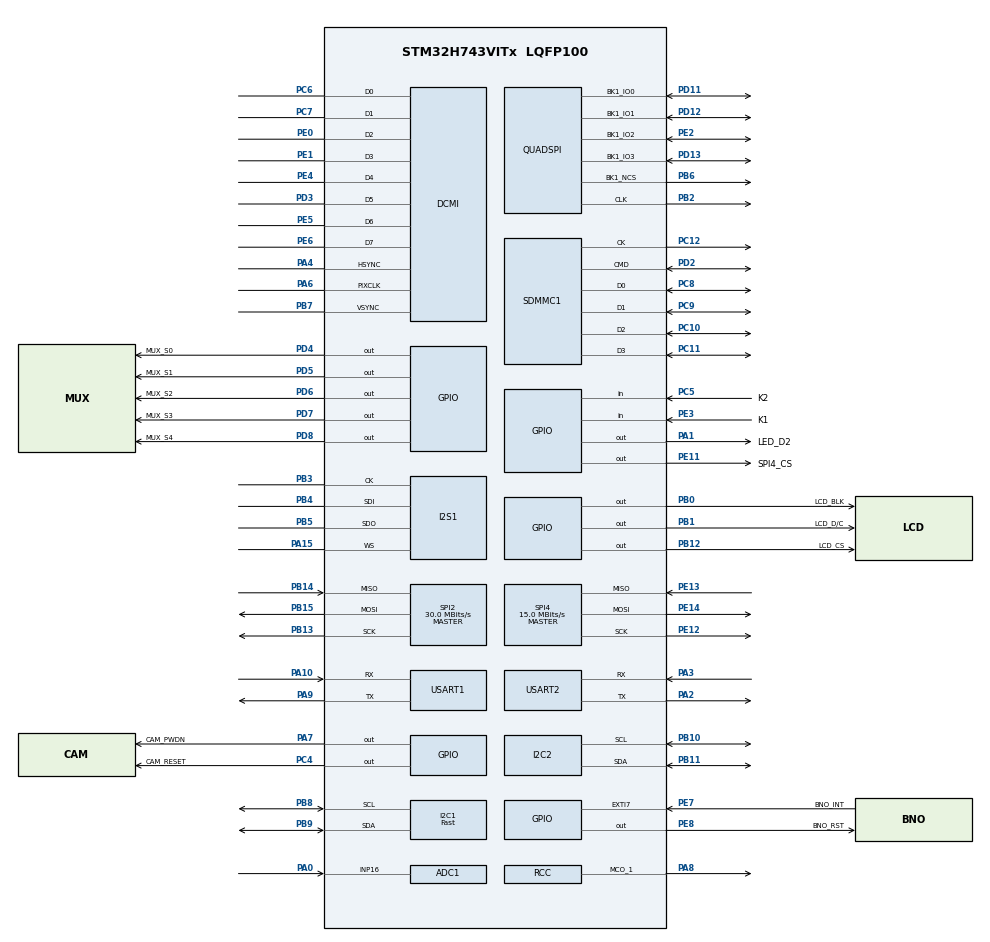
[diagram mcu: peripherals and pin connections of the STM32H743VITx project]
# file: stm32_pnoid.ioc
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ADC1.Channel-0\#ChannelRegularConversion=ADC_CHANNEL_16
ADC1.ClockPrescaler=ADC_CLOCK_ASYNC_DIV4
ADC1.NbrOfConversionFlag=1
ADC1.OffsetNumber-0\#ChannelRegularConversion=ADC_OFFSET_NONE
ADC1.OffsetSignedSaturation-0\#ChannelRegularConversion=DISABLE
ADC1.Rank-0\#ChannelRegularConversion=1
ADC1.Resolution=ADC_RESOLUTION_12B
ADC1.SamplingTime-0\#ChannelRegularConversion=ADC_SAMPLETIME_64CYCLES_5
ADC1.master=1
CORTEX_M7.CPU_ICache=Enabled
CORTEX_M7.default_mode_Activation=1
Dma.DCMI.0.Direction=DMA_PERIPH_TO_MEMORY
Dma.DCMI.0.EventEnable=DISABLE
Dma.DCMI.0.FIFOMode=DMA_FIFOMODE_DISABLE
Dma.DCMI.0.Instance=DMA1_Stream0
Dma.DCMI.0.MemDataAlignment=DMA_MDATAALIGN_WORD
Dma.DCMI.0.MemInc=DMA_MINC_ENABLE
Dma.DCMI.0.Mode=DMA_CIRCULAR
Dma.DCMI.0.PeriphDataAlignment=DMA_PDATAALIGN_WORD
Dma.DCMI.0.PeriphInc=DMA_PINC_DISABLE
Dma.DCMI.0.Polarity=HAL_DMAMUX_REQ_GEN_RISING
Dma.DCMI.0.Priority=DMA_PRIORITY_HIGH
Dma.DCMI.0.RequestNumber=1
Dma.DCMI.0.SignalID=NONE
Dma.DCMI.0.SyncEnable=DISABLE
Dma.DCMI.0.SyncPolarity=HAL_DMAMUX_SYNC_NO_EVENT
Dma.DCMI.0.SyncRequestNumber=1
Dma.DCMI.0.SyncSignalID=NONE
Dma.Request0=DCMI
Dma.Request1=SPI1_TX
Dma.Request2=SPI2_TX
Dma.Request3=SPI4_RX
Dma.Request4=SPI4_TX
Dma.SPI1_TX.1.Direction=DMA_MEMORY_TO_PERIPH
Dma.SPI1_TX.1.EventEnable=DISABLE
Dma.SPI1_TX.1.FIFOMode=DMA_FIFOMODE_DISABLE
Dma.SPI1_TX.1.Instance=DMA1_Stream1
Dma.SPI1_TX.1.MemDataAlignment=DMA_MDATAALIGN_HALFWORD
Dma.SPI1_TX.1.MemInc=DMA_MINC_ENABLE
Dma.SPI1_TX.1.Mode=DMA_CIRCULAR
Dma.SPI1_TX.1.PeriphDataAlignment=DMA_PDATAALIGN_HALFWORD
Dma.SPI1_TX.1.PeriphInc=DMA_PINC_DISABLE
Dma.SPI1_TX.1.Polarity=HAL_DMAMUX_REQ_GEN_RISING
Dma.SPI1_TX.1.Priority=DMA_PRIORITY_HIGH
Dma.SPI1_TX.1.RequestNumber=1
Dma.SPI1_TX.1.SignalID=NONE
Dma.SPI1_TX.1.SyncEnable=DISABLE
Dma.SPI1_TX.1.SyncPolarity=HAL_DMAMUX_SYNC_NO_EVENT
Dma.SPI1_TX.1.SyncRequestNumber=1
Dma.SPI1_TX.1.SyncSignalID=NONE
Dma.SPI2_TX.2.Direction=DMA_MEMORY_TO_PERIPH
Dma.SPI2_TX.2.EventEnable=DISABLE
Dma.SPI2_TX.2.FIFOMode=DMA_FIFOMODE_DISABLE
Dma.SPI2_TX.2.Instance=DMA1_Stream2
Dma.SPI2_TX.2.MemDataAlignment=DMA_MDATAALIGN_BYTE
Dma.SPI2_TX.2.MemInc=DMA_MINC_ENABLE
Dma.SPI2_TX.2.Mode=DMA_NORMAL
Dma.SPI2_TX.2.PeriphDataAlignment=DMA_PDATAALIGN_BYTE
Dma.SPI2_TX.2.PeriphInc=DMA_PINC_DISABLE
Dma.SPI2_TX.2.Polarity=HAL_DMAMUX_REQ_GEN_RISING
Dma.SPI2_TX.2.Priority=DMA_PRIORITY_MEDIUM
Dma.SPI2_TX.2.RequestNumber=1
Dma.SPI2_TX.2.SignalID=NONE
Dma.SPI2_TX.2.SyncEnable=DISABLE
Dma.SPI2_TX.2.SyncPolarity=HAL_DMAMUX_SYNC_NO_EVENT
Dma.SPI2_TX.2.SyncRequestNumber=1
Dma.SPI2_TX.2.SyncSignalID=NONE
Dma.SPI4_RX.3.Direction=DMA_PERIPH_TO_MEMORY
Dma.SPI4_RX.3.EventEnable=DISABLE
Dma.SPI4_RX.3.FIFOMode=DMA_FIFOMODE_DISABLE
Dma.SPI4_RX.3.Instance=DMA1_Stream3
Dma.SPI4_RX.3.MemDataAlignment=DMA_MDATAALIGN_BYTE
Dma.SPI4_RX.3.MemInc=DMA_MINC_ENABLE
Dma.SPI4_RX.3.Mode=DMA_NORMAL
Dma.SPI4_RX.3.PeriphDataAlignment=DMA_PDATAALIGN_BYTE
Dma.SPI4_RX.3.PeriphInc=DMA_PINC_DISABLE
Dma.SPI4_RX.3.Polarity=HAL_DMAMUX_REQ_GEN_RISING
Dma.SPI4_RX.3.Priority=DMA_PRIORITY_MEDIUM
Dma.SPI4_RX.3.RequestNumber=1
Dma.SPI4_RX.3.SignalID=NONE
Dma.SPI4_RX.3.SyncEnable=DISABLE
Dma.SPI4_RX.3.SyncPolarity=HAL_DMAMUX_SYNC_NO_EVENT
Dma.SPI4_RX.3.SyncRequestNumber=1
Dma.SPI4_RX.3.SyncSignalID=NONE
Dma.SPI4_TX.4.Direction=DMA_MEMORY_TO_PERIPH
Dma.SPI4_TX.4.EventEnable=DISABLE
Dma.SPI4_TX.4.FIFOMode=DMA_FIFOMODE_DISABLE
Dma.SPI4_TX.4.Instance=DMA1_Stream4
Dma.SPI4_TX.4.MemDataAlignment=DMA_MDATAALIGN_BYTE
Dma.SPI4_TX.4.MemInc=DMA_MINC_ENABLE
Dma.SPI4_TX.4.Mode=DMA_NORMAL
Dma.SPI4_TX.4.PeriphDataAlignment=DMA_PDATAALIGN_BYTE
Dma.SPI4_TX.4.PeriphInc=DMA_PINC_DISABLE
Dma.SPI4_TX.4.Polarity=HAL_DMAMUX_REQ_GEN_RISING
Dma.SPI4_TX.4.Priority=DMA_PRIORITY_MEDIUM
Dma.SPI4_TX.4.RequestNumber=1
Dma.SPI4_TX.4.SignalID=NONE
Dma.SPI4_TX.4.SyncEnable=DISABLE
Dma.SPI4_TX.4.SyncPolarity=HAL_DMAMUX_SYNC_NO_EVENT
Dma.SPI4_TX.4.SyncRequestNumber=1
Dma.SPI4_TX.4.SyncSignalID=NONE
I2C1.I2C_Speed_Mode=I2C_Fast
I2C1.Timing=0x00B03FDB
I2C2.Timing=0x307075B1
I2S1.AudioFreq=I2S_AUDIOFREQ_16K
I2S1.ErrorAudioFreq=0.15 %
I2S1.Instance=SPI$Index
I2S1.RealAudioFreq=16.025 KHz
Mcu.Family=STM32H7
Mcu.Name=STM32H743VITx
Mcu.Package=LQFP100
NVIC.DCMI_IRQn=true\:5\:0\:true\:false\:true\:true\:true\:true
NVIC.DMA1_Stream0_IRQn=true\:5\:0\:true\:false\:true\:false\:true\:true
NVIC.DMA1_Stream1_IRQn=true\:0\:0\:false\:false\:true\:false\:true\:true
NVIC.DMA1_Stream2_IRQn=true\:0\:0\:false\:false\:true\:false\:true\:true
NVIC.DMA1_Stream3_IRQn=true\:0\:0\:false\:false\:true\:false\:true\:true
NVIC.DMA1_Stream4_IRQn=true\:0\:0\:false\:false\:true\:false\:true\:true
NVIC.EXTI9_5_IRQn=true\:5\:0\:true\:false\:true\:true\:true\:true
NVIC.PriorityGroup=NVIC_PRIORITYGROUP_4
NVIC.SPI2_IRQn=true\:0\:0\:false\:false\:true\:false\:true\:true
NVIC.SPI4_IRQn=true\:0\:0\:false\:false\:true\:false\:true\:true
PA0.Mode=IN16-Single-Ended
PA0.Signal=ADC1_INP16
PA1.GPIO_Label=LED_D2
PA1.GPIO_ModeDefaultOutputPP=GPIO_MODE_OUTPUT_PP
PA1.Signal=GPIO_Output
PA10.Mode=Asynchronous
PA10.Signal=USART1_RX
PA13\ (JTMS/SWDIO).Mode=Serial_Wire
PA13\ (JTMS/SWDIO).Signal=DEBUG_JTMS-SWDIO
PA14\ (JTCK/SWCLK).Mode=Serial_Wire
PA14\ (JTCK/SWCLK).Signal=DEBUG_JTCK-SWCLK
PA15\ (JTDI).Mode=Full_Duplex_Master
PA15\ (JTDI).Signal=I2S1_WS
PA2.Mode=Asynchronous
PA2.Signal=USART2_TX
PA3.Mode=Asynchronous
PA3.Signal=USART2_RX
PA4.Mode=Slave_8_bits_External_Synchro
PA4.Signal=DCMI_HSYNC
PA6.Mode=Slave_8_bits_External_Synchro
PA6.Signal=DCMI_PIXCLK
PA7.GPIO_Label=CAM_PWDN
PA7.Signal=GPIO_Output
PA8.Mode=Clock-out-1
PA8.Signal=RCC_MCO_1
PA9.Mode=Asynchronous
PA9.Signal=USART1_TX
PB0.GPIO_Label=LCD_BLK
PB0.Signal=GPIO_Output
PB1.GPIO_Label=LCD_D/C
PB1.Signal=GPIO_Output
PB10.Mode=I2C
PB10.Signal=I2C2_SCL
PB11.Mode=I2C
PB11.Signal=I2C2_SDA
PB12.GPIO_Label=LCD_CS
PB12.Signal=GPIO_Output
PB13.Mode=Full_Duplex_Master
PB13.Signal=SPI2_SCK
PB14.Mode=Full_Duplex_Master
PB14.Signal=SPI2_MISO
PB15.Mode=Full_Duplex_Master
PB15.Signal=SPI2_MOSI
PB2.GPIO_Speed=GPIO_SPEED_FREQ_VERY_HIGH
PB2.Mode=Single Bank 1
PB2.Signal=QUADSPI_CLK
PB3\ (JTDO/TRACESWO).Mode=Full_Duplex_Master
PB3\ (JTDO/TRACESWO).Signal=I2S1_CK
PB4\ (NJTRST).Mode=Full_Duplex_Master
PB4\ (NJTRST).Signal=I2S1_SDI
PB5.Mode=Full_Duplex_Master
PB5.Signal=I2S1_SDO
PB6.GPIO_Speed=GPIO_SPEED_FREQ_VERY_HIGH
PB6.Mode=Single Bank 1
PB6.Signal=QUADSPI_BK1_NCS
PB7.Mode=Slave_8_bits_External_Synchro
PB7.Signal=DCMI_VSYNC
PB8.Mode=I2C
PB8.Signal=I2C1_SCL
PB9.Mode=I2C
PB9.Signal=I2C1_SDA
PC10.GPIO_PuPd=GPIO_PULLUP
PC10.Mode=SD_4_bits_Wide_bus
PC10.Signal=SDMMC1_D2
PC11.GPIO_PuPd=GPIO_PULLUP
PC11.Mode=SD_4_bits_Wide_bus
PC11.Signal=SDMMC1_D3
PC12.Mode=SD_4_bits_Wide_bus
PC12.Signal=SDMMC1_CK
PC4.GPIO_Label=CAM_RESET
PC4.Signal=GPIO_Output
PC5.GPIO_Label=K2
PC5.GPIO_PuPd=GPIO_PULLUP
PC5.Signal=GPIO_Input
PC6.Mode=Slave_8_bits_External_Synchro
PC6.Signal=DCMI_D0
PC7.Mode=Slave_8_bits_External_Synchro
PC7.Signal=DCMI_D1
PC8.GPIO_PuPd=GPIO_PULLUP
PC8.Mode=SD_4_bits_Wide_bus
PC8.Signal=SDMMC1_D0
PC9.GPIO_PuPd=GPIO_PULLUP
PC9.Mode=SD_4_bits_Wide_bus
PC9.Signal=SDMMC1_D1
PD11.GPIO_Speed=GPIO_SPEED_FREQ_VERY_HIGH
PD11.Mode=Single Bank 1
PD11.Signal=QUADSPI_BK1_IO0
PD12.GPIO_Speed=GPIO_SPEED_FREQ_VERY_HIGH
PD12.Mode=Single Bank 1
PD12.Signal=QUADSPI_BK1_IO1
PD13.GPIO_Speed=GPIO_SPEED_FREQ_VERY_HIGH
PD13.Mode=Single Bank 1
PD13.Signal=QUADSPI_BK1_IO3
PD2.GPIO_PuPd=GPIO_PULLUP
PD2.Mode=SD_4_bits_Wide_bus
PD2.Signal=SDMMC1_CMD
PD3.Mode=Slave_8_bits_External_Synchro
PD3.Signal=DCMI_D5
PD4.GPIO_Label=MUX_S0
PD4.Signal=GPIO_Output
PD5.GPIO_Label=MUX_S1
PD5.Signal=GPIO_Output
PD6.GPIO_Label=MUX_S2
PD6.Signal=GPIO_Output
PD7.GPIO_Label=MUX_S3
PD7.Signal=GPIO_Output
PD8.GPIO_Label=MUX_S4
PD8.Signal=GPIO_Output
PE0.Mode=Slave_8_bits_External_Synchro
PE0.Signal=DCMI_D2
PE1.Mode=Slave_8_bits_External_Synchro
PE1.Signal=DCMI_D3
PE11.GPIO_Label=SPI4_CS
PE11.GPIO_PuPd=GPIO_PULLUP
PE11.GPIO_Speed=GPIO_SPEED_FREQ_HIGH
PE11.PinState=GPIO_PIN_SET
PE11.Signal=GPIO_Output
PE12.Mode=Full_Duplex_Master
PE12.Signal=SPI4_SCK
PE13.Mode=Full_Duplex_Master
PE13.Signal=SPI4_MISO
PE14.Mode=Full_Duplex_Master
PE14.Signal=SPI4_MOSI
PE2.GPIO_Speed=GPIO_SPEED_FREQ_VERY_HIGH
PE2.Mode=Single Bank 1
PE2.Signal=QUADSPI_BK1_IO2
PE3.GPIO_Label=K1
PE3.GPIO_Mode=GPIO_MODE_INPUT
PE3.GPIO_PuPd=GPIO_PULLUP
PE3.Signal=GPIO_Input
PE4.Mode=Slave_8_bits_External_Synchro
PE4.Signal=DCMI_D4
PE5.Mode=Slave_8_bits_External_Synchro
PE5.Signal=DCMI_D6
PE6.Mode=Slave_8_bits_External_Synchro
PE6.Signal=DCMI_D7
PE7.GPIO_Label=BNO_INT
PE7.GPIO_ModeDefaultEXTI=GPIO_MODE_IT_FALLING
PE7.GPIO_PuPd=GPIO_PULLUP
PE7.Signal=GPXTI7
PE8.GPIO_Label=BNO_RST
PE8.GPIO_ModeDefaultOutputPP=GPIO_MODE_OUTPUT_PP
PE8.GPIO_PuPd=GPIO_NOPULL
PE8.PinState=GPIO_PIN_SET
PE8.Signal=GPIO_Output
PH0-OSC_IN\ (PH0).Mode=HSE-External-Oscillator
PH0-OSC_IN\ (PH0).Signal=RCC_OSC_IN
PH1-OSC_OUT\ (PH1).Mode=HSE-External-Oscillator
PH1-OSC_OUT\ (PH1).Signal=RCC_OSC_OUT
ProjectManager.HeapSize=0x200
ProjectManager.StackSize=0x400
ProjectManager.TargetToolchain=STM32CubeIDE
QUADSPI.ClockPrescaler=3
QUADSPI.FifoThreshold=4
QUADSPI.FlashSize=22
QUADSPI.SampleShifting=QSPI_SAMPLE_SHIFTING_HALFCYCLE
RCC.ADCFreq_Value=100000000
RCC.APB1Freq_Value=120000000
RCC.APB2Freq_Value=120000000
RCC.APB3Freq_Value=120000000
RCC.APB4Freq_Value=120000000
RCC.CortexFreq_Value=480000000
RCC.D1PPRE=RCC_APB3_DIV2
RCC.D2PPRE1=RCC_APB1_DIV2
RCC.D2PPRE2=RCC_APB2_DIV2
RCC.D3PPRE=RCC_APB4_DIV2
RCC.DIVM1=5
RCC.DIVM2=25
RCC.DIVM3=5
RCC.DIVN1=192
RCC.DIVN2=400
RCC.DIVN3=192
RCC.DIVP2=4
RCC.DIVQ1=8
RCC.DIVQ3=4
RCC.DIVR3=1
RCC.HCLKFreq_Value=240000000
RCC.HPRE=RCC_HCLK_DIV2
RCC.PLL2FRACN=0
RCC.PLL3FRACN=0
RCC.PLLFRACN=0
RCC.PLLSourceVirtual=RCC_PLLSOURCE_HSE
RCC.RCC_MCO1Source=RCC_MCO1SOURCE_HSE
RCC.SDMMC1CLockSelection=RCC_SDMMCCLKSOURCE_PLL2
RCC.SYSCLKFreq_VALUE=480000000
RCC.SYSCLKSource=RCC_SYSCLKSOURCE_PLLCLK
RCC.USBFreq_Value=120000000
SDMMC1.ClockDiv=16
SPI2.BaudRatePrescaler=SPI_BAUDRATEPRESCALER_4
SPI2.CalculateBaudRate=30.0 MBits/s
SPI2.DataSize=SPI_DATASIZE_8BIT
SPI2.Direction=SPI_DIRECTION_2LINES
SPI2.Mode=SPI_MODE_MASTER
SPI2.VirtualType=VM_MASTER
SPI4.BaudRatePrescaler=SPI_BAUDRATEPRESCALER_8
SPI4.CalculateBaudRate=15.0 MBits/s
SPI4.Direction=SPI_DIRECTION_2LINES
SPI4.Mode=SPI_MODE_MASTER
SPI4.VirtualType=VM_MASTER
USART1.VirtualMode-Asynchronous=VM_ASYNC
USART2.VirtualMode-Asynchronous=VM_ASYNC
VP_FATFS_VS_SDIO.Mode=SDIO
VP_MEMORYMAP_VS_MEMORYMAP.Mode=CurAppReg
VP_TIM1_VS_ClockSourceINT.Mode=Internal
board=custom

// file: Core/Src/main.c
/* USER CODE BEGIN Header */
/**
  ******************************************************************************
  * @file           : main.c
  * @brief          : Main program body
  ******************************************************************************
  * @attention
  *
  * Copyright (c) 2026 STMicroelectronics.
  * All rights reserved.
  *
  * This software is licensed under terms that can be found in the LICENSE file
  * in the root directory of this software component.
  * If no LICENSE file comes with this software, it is provided AS-IS.
  *
  ******************************************************************************
  */
/* USER CODE END Header */
#include "main.h"
#include "fatfs.h"

/* USER CODE BEGIN Includes */
#include "app.hpp"
#include "debug_log.h"
/* USER CODE END Includes */

/* USER CODE BEGIN PM */
static const char *TAG = "MAIN";
/* USER CODE END PM */

ADC_HandleTypeDef hadc1;

DCMI_HandleTypeDef hdcmi;
DMA_HandleTypeDef hdma_dcmi;

I2C_HandleTypeDef hi2c1;
I2C_HandleTypeDef hi2c2;

I2S_HandleTypeDef hi2s1;
DMA_HandleTypeDef hdma_spi1_tx;

QSPI_HandleTypeDef hqspi;

SD_HandleTypeDef hsd1;

SPI_HandleTypeDef hspi2;
SPI_HandleTypeDef hspi4;
DMA_HandleTypeDef hdma_spi2_tx;
DMA_HandleTypeDef hdma_spi4_rx;
DMA_HandleTypeDef hdma_spi4_tx;

TIM_HandleTypeDef htim1;

UART_HandleTypeDef huart1;
UART_HandleTypeDef huart2;

void SystemClock_Config(void);
void PeriphCommonClock_Config(void);
static void MPU_Config(void);
static void MX_GPIO_Init(void);
static void MX_DMA_Init(void);
static void MX_USART1_UART_Init(void);
static void MX_USART2_UART_Init(void);
static void MX_QUADSPI_Init(void);
static void MX_TIM1_Init(void);
static void MX_SDMMC1_SD_Init(void);
static void MX_SPI2_Init(void);
static void MX_DCMI_Init(void);
static void MX_I2C2_Init(void);
static void MX_I2S1_Init(void);
static void MX_ADC1_Init(void);
static void MX_I2C1_Init(void);
static void MX_SPI4_Init(void);

int main(void)
{

  /* MPU Configuration--------------------------------------------------------*/
  MPU_Config();

  /* Enable the CPU Cache */

  /* Enable I-Cache---------------------------------------------------------*/
  SCB_EnableICache();

  /* MCU Configuration--------------------------------------------------------*/

  /* Reset of all peripherals, Initializes the Flash interface and the Systick. */
  HAL_Init();

  /* Configure the system clock */
  SystemClock_Config();

  /* Configure the peripherals common clocks */
  PeriphCommonClock_Config();

  /* Initialize all configured peripherals */
  MX_GPIO_Init();
  MX_DMA_Init();
  MX_USART1_UART_Init();
  MX_USART2_UART_Init();
  MX_QUADSPI_Init();
  MX_TIM1_Init();
  MX_SDMMC1_SD_Init();
  MX_SPI2_Init();
  MX_DCMI_Init();
  MX_I2C2_Init();
  MX_FATFS_Init();
  MX_I2S1_Init();
  MX_ADC1_Init();
  MX_I2C1_Init();
  MX_SPI4_Init();
  /* USER CODE BEGIN 2 */
  App_Init();
  /* USER CODE END 2 */

  /* Infinite loop */
  while (1)
  {

    /* USER CODE BEGIN 3 */
    App_Main();
  }
  /* USER CODE END 3 */
}

void SystemClock_Config(void)
{
  RCC_OscInitTypeDef RCC_OscInitStruct = {0};
  RCC_ClkInitTypeDef RCC_ClkInitStruct = {0};

  /** Supply configuration update enable
  */
  HAL_PWREx_ConfigSupply(PWR_LDO_SUPPLY);

  /** Configure the main internal regulator output voltage
  */
  __HAL_PWR_VOLTAGESCALING_CONFIG(PWR_REGULATOR_VOLTAGE_SCALE0);

  while(!__HAL_PWR_GET_FLAG(PWR_FLAG_VOSRDY)) {}

  /** Initializes the RCC Oscillators according to the specified parameters
  * in the RCC_OscInitTypeDef structure.
  */
  RCC_OscInitStruct.OscillatorType = RCC_OSCILLATORTYPE_HSE;
  RCC_OscInitStruct.HSEState = RCC_HSE_ON;
  RCC_OscInitStruct.PLL.PLLState = RCC_PLL_ON;
  RCC_OscInitStruct.PLL.PLLSource = RCC_PLLSOURCE_HSE;
  RCC_OscInitStruct.PLL.PLLM = 5;
  RCC_OscInitStruct.PLL.PLLN = 192;
  RCC_OscInitStruct.PLL.PLLP = 2;
  RCC_OscInitStruct.PLL.PLLQ = 8;
  RCC_OscInitStruct.PLL.PLLR = 2;
  RCC_OscInitStruct.PLL.PLLRGE = RCC_PLL1VCIRANGE_2;
  RCC_OscInitStruct.PLL.PLLVCOSEL = RCC_PLL1VCOWIDE;
  RCC_OscInitStruct.PLL.PLLFRACN = 0;
  if (HAL_RCC_OscConfig(&RCC_OscInitStruct) != HAL_OK)
  {
    Error_Handler();
  }

  /** Initializes the CPU, AHB and APB buses clocks
  */
  RCC_ClkInitStruct.ClockType = RCC_CLOCKTYPE_HCLK|RCC_CLOCKTYPE_SYSCLK
                              |RCC_CLOCKTYPE_PCLK1|RCC_CLOCKTYPE_PCLK2
                              |RCC_CLOCKTYPE_D3PCLK1|RCC_CLOCKTYPE_D1PCLK1;
  RCC_ClkInitStruct.SYSCLKSource = RCC_SYSCLKSOURCE_PLLCLK;
  RCC_ClkInitStruct.SYSCLKDivider = RCC_SYSCLK_DIV1;
  RCC_ClkInitStruct.AHBCLKDivider = RCC_HCLK_DIV2;
  RCC_ClkInitStruct.APB3CLKDivider = RCC_APB3_DIV2;
  RCC_ClkInitStruct.APB1CLKDivider = RCC_APB1_DIV2;
  RCC_ClkInitStruct.APB2CLKDivider = RCC_APB2_DIV2;
  RCC_ClkInitStruct.APB4CLKDivider = RCC_APB4_DIV2;

  if (HAL_RCC_ClockConfig(&RCC_ClkInitStruct, FLASH_LATENCY_4) != HAL_OK)
  {
    Error_Handler();
  }
  HAL_RCC_MCOConfig(RCC_MCO1, RCC_MCO1SOURCE_HSE, RCC_MCODIV_1);
}

void PeriphCommonClock_Config(void)
{
  RCC_PeriphCLKInitTypeDef PeriphClkInitStruct = {0};

  /** Initializes the peripherals clock
  */
  PeriphClkInitStruct.PeriphClockSelection = RCC_PERIPHCLK_ADC|RCC_PERIPHCLK_SDMMC;
  PeriphClkInitStruct.PLL2.PLL2M = 25;
  PeriphClkInitStruct.PLL2.PLL2N = 400;
  PeriphClkInitStruct.PLL2.PLL2P = 4;
  PeriphClkInitStruct.PLL2.PLL2Q = 2;
  PeriphClkInitStruct.PLL2.PLL2R = 2;
  PeriphClkInitStruct.PLL2.PLL2RGE = RCC_PLL2VCIRANGE_0;
  PeriphClkInitStruct.PLL2.PLL2VCOSEL = RCC_PLL2VCOWIDE;
  PeriphClkInitStruct.PLL2.PLL2FRACN = 0;
  PeriphClkInitStruct.SdmmcClockSelection = RCC_SDMMCCLKSOURCE_PLL2;
  PeriphClkInitStruct.AdcClockSelection = RCC_ADCCLKSOURCE_PLL2;
  if (HAL_RCCEx_PeriphCLKConfig(&PeriphClkInitStruct) != HAL_OK)
  {
    Error_Handler();
  }
}

static void MX_ADC1_Init(void)
{

  ADC_MultiModeTypeDef multimode = {0};
  ADC_ChannelConfTypeDef sConfig = {0};

  /** Common config
  */
  hadc1.Instance = ADC1;
  hadc1.Init.ClockPrescaler = ADC_CLOCK_ASYNC_DIV4;
  hadc1.Init.Resolution = ADC_RESOLUTION_12B;
  hadc1.Init.ScanConvMode = ADC_SCAN_DISABLE;
  hadc1.Init.EOCSelection = ADC_EOC_SINGLE_CONV;
  hadc1.Init.LowPowerAutoWait = DISABLE;
  hadc1.Init.ContinuousConvMode = DISABLE;
  hadc1.Init.NbrOfConversion = 1;
  hadc1.Init.DiscontinuousConvMode = DISABLE;
  hadc1.Init.ExternalTrigConv = ADC_SOFTWARE_START;
  hadc1.Init.ExternalTrigConvEdge = ADC_EXTERNALTRIGCONVEDGE_NONE;
  hadc1.Init.ConversionDataManagement = ADC_CONVERSIONDATA_DR;
  hadc1.Init.Overrun = ADC_OVR_DATA_PRESERVED;
  hadc1.Init.LeftBitShift = ADC_LEFTBITSHIFT_NONE;
  hadc1.Init.OversamplingMode = DISABLE;
  hadc1.Init.Oversampling.Ratio = 1;
  if (HAL_ADC_Init(&hadc1) != HAL_OK)
  {
    Error_Handler();
  }

  /** Configure the ADC multi-mode
  */
  multimode.Mode = ADC_MODE_INDEPENDENT;
  if (HAL_ADCEx_MultiModeConfigChannel(&hadc1, &multimode) != HAL_OK)
  {
    Error_Handler();
  }

  /** Configure Regular Channel
  */
  sConfig.Channel = ADC_CHANNEL_16;
  sConfig.Rank = ADC_REGULAR_RANK_1;
  sConfig.SamplingTime = ADC_SAMPLETIME_64CYCLES_5;
  sConfig.SingleDiff = ADC_SINGLE_ENDED;
  sConfig.OffsetNumber = ADC_OFFSET_NONE;
  sConfig.Offset = 0;
  sConfig.OffsetSignedSaturation = DISABLE;
  if (HAL_ADC_ConfigChannel(&hadc1, &sConfig) != HAL_OK)
  {
    Error_Handler();
  }

}

static void MX_DCMI_Init(void)
{

  hdcmi.Instance = DCMI;
  hdcmi.Init.SynchroMode = DCMI_SYNCHRO_HARDWARE;
  hdcmi.Init.PCKPolarity = DCMI_PCKPOLARITY_FALLING;
  hdcmi.Init.VSPolarity = DCMI_VSPOLARITY_LOW;
  hdcmi.Init.HSPolarity = DCMI_HSPOLARITY_LOW;
  hdcmi.Init.CaptureRate = DCMI_CR_ALL_FRAME;
  hdcmi.Init.ExtendedDataMode = DCMI_EXTEND_DATA_8B;
  hdcmi.Init.JPEGMode = DCMI_JPEG_DISABLE;
  hdcmi.Init.ByteSelectMode = DCMI_BSM_ALL;
  hdcmi.Init.ByteSelectStart = DCMI_OEBS_ODD;
  hdcmi.Init.LineSelectMode = DCMI_LSM_ALL;
  hdcmi.Init.LineSelectStart = DCMI_OELS_ODD;
  if (HAL_DCMI_Init(&hdcmi) != HAL_OK)
  {
    Error_Handler();
  }

}

static void MX_I2C1_Init(void)
{

  hi2c1.Instance = I2C1;
  hi2c1.Init.Timing = 0x00B03FDB;
  hi2c1.Init.OwnAddress1 = 0;
  hi2c1.Init.AddressingMode = I2C_ADDRESSINGMODE_7BIT;
  hi2c1.Init.DualAddressMode = I2C_DUALADDRESS_DISABLE;
  hi2c1.Init.OwnAddress2 = 0;
  hi2c1.Init.OwnAddress2Masks = I2C_OA2_NOMASK;
  hi2c1.Init.GeneralCallMode = I2C_GENERALCALL_DISABLE;
  hi2c1.Init.NoStretchMode = I2C_NOSTRETCH_DISABLE;
  if (HAL_I2C_Init(&hi2c1) != HAL_OK)
  {
    Error_Handler();
  }

  /** Configure Analogue filter
  */
  if (HAL_I2CEx_ConfigAnalogFilter(&hi2c1, I2C_ANALOGFILTER_ENABLE) != HAL_OK)
  {
    Error_Handler();
  }

  /** Configure Digital filter
  */
  if (HAL_I2CEx_ConfigDigitalFilter(&hi2c1, 0) != HAL_OK)
  {
    Error_Handler();
  }

}

static void MX_I2C2_Init(void)
{

  hi2c2.Instance = I2C2;
  hi2c2.Init.Timing = 0x307075B1;
  hi2c2.Init.OwnAddress1 = 0;
  hi2c2.Init.AddressingMode = I2C_ADDRESSINGMODE_7BIT;
  hi2c2.Init.DualAddressMode = I2C_DUALADDRESS_DISABLE;
  hi2c2.Init.OwnAddress2 = 0;
  hi2c2.Init.OwnAddress2Masks = I2C_OA2_NOMASK;
  hi2c2.Init.GeneralCallMode = I2C_GENERALCALL_DISABLE;
  hi2c2.Init.NoStretchMode = I2C_NOSTRETCH_DISABLE;
  if (HAL_I2C_Init(&hi2c2) != HAL_OK)
  {
    Error_Handler();
  }

  /** Configure Analogue filter
  */
  if (HAL_I2CEx_ConfigAnalogFilter(&hi2c2, I2C_ANALOGFILTER_ENABLE) != HAL_OK)
  {
    Error_Handler();
  }

  /** Configure Digital filter
  */
  if (HAL_I2CEx_ConfigDigitalFilter(&hi2c2, 0) != HAL_OK)
  {
    Error_Handler();
  }

}

static void MX_I2S1_Init(void)
{

  hi2s1.Instance = SPI1;
  hi2s1.Init.Mode = I2S_MODE_MASTER_FULLDUPLEX;
  hi2s1.Init.Standard = I2S_STANDARD_PHILIPS;
  hi2s1.Init.DataFormat = I2S_DATAFORMAT_16B;
  hi2s1.Init.MCLKOutput = I2S_MCLKOUTPUT_DISABLE;
  hi2s1.Init.AudioFreq = I2S_AUDIOFREQ_16K;
  hi2s1.Init.CPOL = I2S_CPOL_LOW;
  hi2s1.Init.FirstBit = I2S_FIRSTBIT_MSB;
  hi2s1.Init.WSInversion = I2S_WS_INVERSION_DISABLE;
  hi2s1.Init.Data24BitAlignment = I2S_DATA_24BIT_ALIGNMENT_RIGHT;
  hi2s1.Init.MasterKeepIOState = I2S_MASTER_KEEP_IO_STATE_DISABLE;
  if (HAL_I2S_Init(&hi2s1) != HAL_OK)
  {
    Error_Handler();
  }

}

static void MX_QUADSPI_Init(void)
{

  /* QUADSPI parameter configuration*/
  hqspi.Instance = QUADSPI;
  hqspi.Init.ClockPrescaler = 3;
  hqspi.Init.FifoThreshold = 4;
  hqspi.Init.SampleShifting = QSPI_SAMPLE_SHIFTING_HALFCYCLE;
  hqspi.Init.FlashSize = 22;
  hqspi.Init.ChipSelectHighTime = QSPI_CS_HIGH_TIME_1_CYCLE;
  hqspi.Init.ClockMode = QSPI_CLOCK_MODE_0;
  hqspi.Init.FlashID = QSPI_FLASH_ID_1;
  hqspi.Init.DualFlash = QSPI_DUALFLASH_DISABLE;
  if (HAL_QSPI_Init(&hqspi) != HAL_OK)
  {
    Error_Handler();
  }

}

static void MX_SDMMC1_SD_Init(void)
{

  /* USER CODE BEGIN SDMMC1_Init 1 */
  /* Skip CubeMX HAL_SD_Init — we handle SD init in app.cpp (SDCard::init)
     to avoid Error_Handler() when no SD card is inserted. */
  return;
  /* USER CODE END SDMMC1_Init 1 */
  hsd1.Instance = SDMMC1;
  hsd1.Init.ClockEdge = SDMMC_CLOCK_EDGE_RISING;
  hsd1.Init.ClockPowerSave = SDMMC_CLOCK_POWER_SAVE_DISABLE;
  hsd1.Init.BusWide = SDMMC_BUS_WIDE_4B;
  hsd1.Init.HardwareFlowControl = SDMMC_HARDWARE_FLOW_CONTROL_DISABLE;
  hsd1.Init.ClockDiv = 16;
  if (HAL_SD_Init(&hsd1) != HAL_OK)
  {
    Error_Handler();
  }

}

static void MX_SPI2_Init(void)
{

  /* SPI2 parameter configuration*/
  hspi2.Instance = SPI2;
  hspi2.Init.Mode = SPI_MODE_MASTER;
  hspi2.Init.Direction = SPI_DIRECTION_2LINES;
  hspi2.Init.DataSize = SPI_DATASIZE_8BIT;
  hspi2.Init.CLKPolarity = SPI_POLARITY_LOW;
  hspi2.Init.CLKPhase = SPI_PHASE_1EDGE;
  hspi2.Init.NSS = SPI_NSS_SOFT;
  hspi2.Init.BaudRatePrescaler = SPI_BAUDRATEPRESCALER_4;
  hspi2.Init.FirstBit = SPI_FIRSTBIT_MSB;
  hspi2.Init.TIMode = SPI_TIMODE_DISABLE;
  hspi2.Init.CRCCalculation = SPI_CRCCALCULATION_DISABLE;
  hspi2.Init.CRCPolynomial = 0x0;
  hspi2.Init.NSSPMode = SPI_NSS_PULSE_ENABLE;
  hspi2.Init.NSSPolarity = SPI_NSS_POLARITY_LOW;
  hspi2.Init.FifoThreshold = SPI_FIFO_THRESHOLD_01DATA;
  hspi2.Init.TxCRCInitializationPattern = SPI_CRC_INITIALIZATION_ALL_ZERO_PATTERN;
  hspi2.Init.RxCRCInitializationPattern = SPI_CRC_INITIALIZATION_ALL_ZERO_PATTERN;
  hspi2.Init.MasterSSIdleness = SPI_MASTER_SS_IDLENESS_00CYCLE;
  hspi2.Init.MasterInterDataIdleness = SPI_MASTER_INTERDATA_IDLENESS_00CYCLE;
  hspi2.Init.MasterReceiverAutoSusp = SPI_MASTER_RX_AUTOSUSP_DISABLE;
  hspi2.Init.MasterKeepIOState = SPI_MASTER_KEEP_IO_STATE_DISABLE;
  hspi2.Init.IOSwap = SPI_IO_SWAP_DISABLE;
  if (HAL_SPI_Init(&hspi2) != HAL_OK)
  {
    Error_Handler();
  }

}

static void MX_SPI4_Init(void)
{

  /* SPI4 parameter configuration*/
  hspi4.Instance = SPI4;
  hspi4.Init.Mode = SPI_MODE_MASTER;
  hspi4.Init.Direction = SPI_DIRECTION_2LINES;
  hspi4.Init.DataSize = SPI_DATASIZE_4BIT;
  hspi4.Init.CLKPolarity = SPI_POLARITY_LOW;
  hspi4.Init.CLKPhase = SPI_PHASE_1EDGE;
  hspi4.Init.NSS = SPI_NSS_SOFT;
  hspi4.Init.BaudRatePrescaler = SPI_BAUDRATEPRESCALER_8;
  hspi4.Init.FirstBit = SPI_FIRSTBIT_MSB;
  hspi4.Init.TIMode = SPI_TIMODE_DISABLE;
  hspi4.Init.CRCCalculation = SPI_CRCCALCULATION_DISABLE;
  hspi4.Init.CRCPolynomial = 0x0;
  hspi4.Init.NSSPMode = SPI_NSS_PULSE_ENABLE;
  hspi4.Init.NSSPolarity = SPI_NSS_POLARITY_LOW;
  hspi4.Init.FifoThreshold = SPI_FIFO_THRESHOLD_01DATA;
  hspi4.Init.TxCRCInitializationPattern = SPI_CRC_INITIALIZATION_ALL_ZERO_PATTERN;
  hspi4.Init.RxCRCInitializationPattern = SPI_CRC_INITIALIZATION_ALL_ZERO_PATTERN;
  hspi4.Init.MasterSSIdleness = SPI_MASTER_SS_IDLENESS_00CYCLE;
  hspi4.Init.MasterInterDataIdleness = SPI_MASTER_INTERDATA_IDLENESS_00CYCLE;
  hspi4.Init.MasterReceiverAutoSusp = SPI_MASTER_RX_AUTOSUSP_DISABLE;
  hspi4.Init.MasterKeepIOState = SPI_MASTER_KEEP_IO_STATE_DISABLE;
  hspi4.Init.IOSwap = SPI_IO_SWAP_DISABLE;
  if (HAL_SPI_Init(&hspi4) != HAL_OK)
  {
    Error_Handler();
  }

}

static void MX_TIM1_Init(void)
{

  TIM_ClockConfigTypeDef sClockSourceConfig = {0};
  TIM_MasterConfigTypeDef sMasterConfig = {0};

  htim1.Instance = TIM1;
  htim1.Init.Prescaler = 0;
  htim1.Init.CounterMode = TIM_COUNTERMODE_UP;
  htim1.Init.Period = 65535;
  htim1.Init.ClockDivision = TIM_CLOCKDIVISION_DIV1;
  htim1.Init.RepetitionCounter = 0;
  htim1.Init.AutoReloadPreload = TIM_AUTORELOAD_PRELOAD_DISABLE;
  if (HAL_TIM_Base_Init(&htim1) != HAL_OK)
  {
    Error_Handler();
  }
  sClockSourceConfig.ClockSource = TIM_CLOCKSOURCE_INTERNAL;
  if (HAL_TIM_ConfigClockSource(&htim1, &sClockSourceConfig) != HAL_OK)
  {
    Error_Handler();
  }
  sMasterConfig.MasterOutputTrigger = TIM_TRGO_RESET;
  sMasterConfig.MasterOutputTrigger2 = TIM_TRGO2_RESET;
  sMasterConfig.MasterSlaveMode = TIM_MASTERSLAVEMODE_DISABLE;
  if (HAL_TIMEx_MasterConfigSynchronization(&htim1, &sMasterConfig) != HAL_OK)
  {
    Error_Handler();
  }

}

static void MX_USART1_UART_Init(void)
{

  huart1.Instance = USART1;
  huart1.Init.BaudRate = 115200;
  huart1.Init.WordLength = UART_WORDLENGTH_8B;
  huart1.Init.StopBits = UART_STOPBITS_1;
  huart1.Init.Parity = UART_PARITY_NONE;
  huart1.Init.Mode = UART_MODE_TX_RX;
  huart1.Init.HwFlowCtl = UART_HWCONTROL_NONE;
  huart1.Init.OverSampling = UART_OVERSAMPLING_16;
  huart1.Init.OneBitSampling = UART_ONE_BIT_SAMPLE_DISABLE;
  huart1.Init.ClockPrescaler = UART_PRESCALER_DIV1;
  huart1.AdvancedInit.AdvFeatureInit = UART_ADVFEATURE_NO_INIT;
  if (HAL_UART_Init(&huart1) != HAL_OK)
  {
    Error_Handler();
  }
  if (HAL_UARTEx_SetTxFifoThreshold(&huart1, UART_TXFIFO_THRESHOLD_1_8) != HAL_OK)
  {
    Error_Handler();
  }
  if (HAL_UARTEx_SetRxFifoThreshold(&huart1, UART_RXFIFO_THRESHOLD_1_8) != HAL_OK)
  {
    Error_Handler();
  }
  if (HAL_UARTEx_DisableFifoMode(&huart1) != HAL_OK)
  {
    Error_Handler();
  }

}

static void MX_USART2_UART_Init(void)
{

  huart2.Instance = USART2;
  huart2.Init.BaudRate = 115200;
  huart2.Init.WordLength = UART_WORDLENGTH_8B;
  huart2.Init.StopBits = UART_STOPBITS_1;
  huart2.Init.Parity = UART_PARITY_NONE;
  huart2.Init.Mode = UART_MODE_TX_RX;
  huart2.Init.HwFlowCtl = UART_HWCONTROL_NONE;
  huart2.Init.OverSampling = UART_OVERSAMPLING_16;
  huart2.Init.OneBitSampling = UART_ONE_BIT_SAMPLE_DISABLE;
  huart2.Init.ClockPrescaler = UART_PRESCALER_DIV1;
  huart2.AdvancedInit.AdvFeatureInit = UART_ADVFEATURE_NO_INIT;
  if (HAL_UART_Init(&huart2) != HAL_OK)
  {
    Error_Handler();
  }
  if (HAL_UARTEx_SetTxFifoThreshold(&huart2, UART_TXFIFO_THRESHOLD_1_8) != HAL_OK)
  {
    Error_Handler();
  }
  if (HAL_UARTEx_SetRxFifoThreshold(&huart2, UART_RXFIFO_THRESHOLD_1_8) != HAL_OK)
  {
    Error_Handler();
  }
  if (HAL_UARTEx_DisableFifoMode(&huart2) != HAL_OK)
  {
    Error_Handler();
  }

}

static void MX_DMA_Init(void)
{

  /* DMA controller clock enable */
  __HAL_RCC_DMA1_CLK_ENABLE();

  /* DMA interrupt init */
  /* DMA1_Stream0_IRQn interrupt configuration */
  HAL_NVIC_SetPriority(DMA1_Stream0_IRQn, 5, 0);
  HAL_NVIC_EnableIRQ(DMA1_Stream0_IRQn);
  /* DMA1_Stream1_IRQn interrupt configuration */
  HAL_NVIC_SetPriority(DMA1_Stream1_IRQn, 0, 0);
  HAL_NVIC_EnableIRQ(DMA1_Stream1_IRQn);
  /* DMA1_Stream2_IRQn interrupt configuration */
  HAL_NVIC_SetPriority(DMA1_Stream2_IRQn, 0, 0);
  HAL_NVIC_EnableIRQ(DMA1_Stream2_IRQn);
  /* DMA1_Stream3_IRQn interrupt configuration */
  HAL_NVIC_SetPriority(DMA1_Stream3_IRQn, 0, 0);
  HAL_NVIC_EnableIRQ(DMA1_Stream3_IRQn);
  /* DMA1_Stream4_IRQn interrupt configuration */
  HAL_NVIC_SetPriority(DMA1_Stream4_IRQn, 0, 0);
  HAL_NVIC_EnableIRQ(DMA1_Stream4_IRQn);

}

static void MX_GPIO_Init(void)
{
  GPIO_InitTypeDef GPIO_InitStruct = {0};

  /* GPIO Ports Clock Enable */
  __HAL_RCC_GPIOE_CLK_ENABLE();
  __HAL_RCC_GPIOH_CLK_ENABLE();
  __HAL_RCC_GPIOA_CLK_ENABLE();
  __HAL_RCC_GPIOC_CLK_ENABLE();
  __HAL_RCC_GPIOB_CLK_ENABLE();
  __HAL_RCC_GPIOD_CLK_ENABLE();

  /*Configure GPIO pin Output Level */
  HAL_GPIO_WritePin(GPIOA, LED_D2_Pin|CAM_PWDN_Pin, GPIO_PIN_RESET);

  /*Configure GPIO pin Output Level */
  HAL_GPIO_WritePin(CAM_RESET_GPIO_Port, CAM_RESET_Pin, GPIO_PIN_RESET);

  /*Configure GPIO pin Output Level */
  HAL_GPIO_WritePin(GPIOB, LCD_BLK_Pin|LCD_D_C_Pin|LCD_CS_Pin, GPIO_PIN_RESET);

  /*Configure GPIO pin Output Level */
  HAL_GPIO_WritePin(GPIOE, BNO_RST_Pin|SPI4_CS_Pin, GPIO_PIN_SET);

  /*Configure GPIO pin Output Level */
  HAL_GPIO_WritePin(GPIOD, MUX_S4_Pin|MUX_S0_Pin|MUX_S1_Pin|MUX_S2_Pin
                          |MUX_S3_Pin, GPIO_PIN_RESET);

  /*Configure GPIO pin : K1_Pin */
  GPIO_InitStruct.Pin = K1_Pin;
  GPIO_InitStruct.Mode = GPIO_MODE_INPUT;
  GPIO_InitStruct.Pull = GPIO_PULLUP;
  HAL_GPIO_Init(K1_GPIO_Port, &GPIO_InitStruct);

  /*Configure GPIO pins : LED_D2_Pin CAM_PWDN_Pin */
  GPIO_InitStruct.Pin = LED_D2_Pin|CAM_PWDN_Pin;
  GPIO_InitStruct.Mode = GPIO_MODE_OUTPUT_PP;
  GPIO_InitStruct.Pull = GPIO_NOPULL;
  GPIO_InitStruct.Speed = GPIO_SPEED_FREQ_LOW;
  HAL_GPIO_Init(GPIOA, &GPIO_InitStruct);

  /*Configure GPIO pin : CAM_RESET_Pin */
  GPIO_InitStruct.Pin = CAM_RESET_Pin;
  GPIO_InitStruct.Mode = GPIO_MODE_OUTPUT_PP;
  GPIO_InitStruct.Pull = GPIO_NOPULL;
  GPIO_InitStruct.Speed = GPIO_SPEED_FREQ_LOW;
  HAL_GPIO_Init(CAM_RESET_GPIO_Port, &GPIO_InitStruct);

  /*Configure GPIO pin : K2_Pin */
  GPIO_InitStruct.Pin = K2_Pin;
  GPIO_InitStruct.Mode = GPIO_MODE_INPUT;
  GPIO_InitStruct.Pull = GPIO_PULLUP;
  HAL_GPIO_Init(K2_GPIO_Port, &GPIO_InitStruct);

  /*Configure GPIO pins : LCD_BLK_Pin LCD_D_C_Pin LCD_CS_Pin */
  GPIO_InitStruct.Pin = LCD_BLK_Pin|LCD_D_C_Pin|LCD_CS_Pin;
  GPIO_InitStruct.Mode = GPIO_MODE_OUTPUT_PP;
  GPIO_InitStruct.Pull = GPIO_NOPULL;
  GPIO_InitStruct.Speed = GPIO_SPEED_FREQ_LOW;
  HAL_GPIO_Init(GPIOB, &GPIO_InitStruct);

  /*Configure GPIO pin : BNO_INT_Pin */
  GPIO_InitStruct.Pin = BNO_INT_Pin;
  GPIO_InitStruct.Mode = GPIO_MODE_IT_FALLING;
  GPIO_InitStruct.Pull = GPIO_PULLUP;
  HAL_GPIO_Init(BNO_INT_GPIO_Port, &GPIO_InitStruct);

  /*Configure GPIO pin : BNO_RST_Pin */
  GPIO_InitStruct.Pin = BNO_RST_Pin;
  GPIO_InitStruct.Mode = GPIO_MODE_OUTPUT_PP;
  GPIO_InitStruct.Pull = GPIO_NOPULL;
  GPIO_InitStruct.Speed = GPIO_SPEED_FREQ_LOW;
  HAL_GPIO_Init(BNO_RST_GPIO_Port, &GPIO_InitStruct);

  /*Configure GPIO pin : SPI4_CS_Pin */
  GPIO_InitStruct.Pin = SPI4_CS_Pin;
  GPIO_InitStruct.Mode = GPIO_MODE_OUTPUT_PP;
  GPIO_InitStruct.Pull = GPIO_PULLUP;
  GPIO_InitStruct.Speed = GPIO_SPEED_FREQ_HIGH;
  HAL_GPIO_Init(SPI4_CS_GPIO_Port, &GPIO_InitStruct);

  /*Configure GPIO pins : MUX_S4_Pin MUX_S0_Pin MUX_S1_Pin MUX_S2_Pin
                           MUX_S3_Pin */
  GPIO_InitStruct.Pin = MUX_S4_Pin|MUX_S0_Pin|MUX_S1_Pin|MUX_S2_Pin
                          |MUX_S3_Pin;
  GPIO_InitStruct.Mode = GPIO_MODE_OUTPUT_PP;
  GPIO_InitStruct.Pull = GPIO_NOPULL;
  GPIO_InitStruct.Speed = GPIO_SPEED_FREQ_LOW;
  HAL_GPIO_Init(GPIOD, &GPIO_InitStruct);

  /*Configure GPIO pin : PA8 */
  GPIO_InitStruct.Pin = GPIO_PIN_8;
  GPIO_InitStruct.Mode = GPIO_MODE_AF_PP;
  GPIO_InitStruct.Pull = GPIO_NOPULL;
  GPIO_InitStruct.Speed = GPIO_SPEED_FREQ_LOW;
  GPIO_InitStruct.Alternate = GPIO_AF0_MCO;
  HAL_GPIO_Init(GPIOA, &GPIO_InitStruct);

  /*AnalogSwitch Config */
  HAL_SYSCFG_AnalogSwitchConfig(SYSCFG_SWITCH_PA1, SYSCFG_SWITCH_PA1_CLOSE);

  /* EXTI interrupt init*/
  HAL_NVIC_SetPriority(BNO_INT_EXTI_IRQn, 5, 0);
  HAL_NVIC_EnableIRQ(BNO_INT_EXTI_IRQn);

}

 /* MPU Configuration */

void MPU_Config(void)
{
  MPU_Region_InitTypeDef MPU_InitStruct = {0};

  /* Disables the MPU */
  HAL_MPU_Disable();

  /** Initializes and configures the Region and the memory to be protected
  */
  MPU_InitStruct.Enable = MPU_REGION_ENABLE;
  MPU_InitStruct.Number = MPU_REGION_NUMBER0;
  MPU_InitStruct.BaseAddress = 0x0;
  MPU_InitStruct.Size = MPU_REGION_SIZE_4GB;
  MPU_InitStruct.SubRegionDisable = 0x87;
  MPU_InitStruct.TypeExtField = MPU_TEX_LEVEL0;
  MPU_InitStruct.AccessPermission = MPU_REGION_NO_ACCESS;
  MPU_InitStruct.DisableExec = MPU_INSTRUCTION_ACCESS_DISABLE;
  MPU_InitStruct.IsShareable = MPU_ACCESS_SHAREABLE;
  MPU_InitStruct.IsCacheable = MPU_ACCESS_NOT_CACHEABLE;
  MPU_InitStruct.IsBufferable = MPU_ACCESS_NOT_BUFFERABLE;

  HAL_MPU_ConfigRegion(&MPU_InitStruct);
  /* Enables the MPU */
  HAL_MPU_Enable(MPU_PRIVILEGED_DEFAULT);

}

void Error_Handler(void)
{
  __disable_irq();
  while (1)
  {
  }
}
